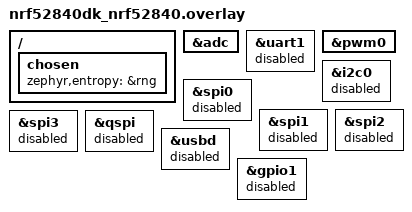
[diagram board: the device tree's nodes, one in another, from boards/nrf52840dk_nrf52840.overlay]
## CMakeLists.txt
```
#
# Copyright (c) 2020 Nordic Semiconductor ASA
#
# SPDX-License-Identifier: LicenseRef-Nordic-5-Clause
#
cmake_minimum_required(VERSION 3.20.0)

list(APPEND BOARD_ROOT ${CMAKE_CURRENT_SOURCE_DIR})

list(INSERT OVERLAY_CONFIG 0 ../common/overlay-ot-defaults.conf)

find_package(Zephyr REQUIRED HINTS $ENV{ZEPHYR_BASE})

project(openthread_coap_client)

# NORDIC SDK APP START
target_sources(app PRIVATE src/coap_client.c
			   src/coap_client_utils.c)

target_include_directories(app PUBLIC ../coap_server/interface)
# NORDIC SDK APP END

# target_sources_ifdef(CONFIG_BT_NUS app PRIVATE src/ble_utils.c)

zephyr_include_directories(include)
add_subdirectory(drivers)
```

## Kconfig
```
#
# Copyright (c) 2020 Nordic Semiconductor ASA
#
# SPDX-License-Identifier: LicenseRef-Nordic-5-Clause
#

menu "Zephyr Kernel"
source "Kconfig.zephyr"
endmenu

rsource "drivers/Kconfig"

module = COAP_CLIENT
module-str = CoAP client
source "${ZEPHYR_BASE}/subsys/logging/Kconfig.template.log_config"

module = COAP_CLIENT_UTILS
module-str = CoAP client utilities
source "${ZEPHYR_BASE}/subsys/logging/Kconfig.template.log_config"
```

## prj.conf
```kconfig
#
# Copyright (c) 2020 Nordic Semiconductor
#
# SPDX-License-Identifier: LicenseRef-Nordic-5-Clause
#


# nRF board library
CONFIG_DK_LIBRARY=y

# Enable CoAP utils and CoAP protocol
CONFIG_COAP_UTILS=y

# Configure sample logging setting
CONFIG_COAP_CLIENT_LOG_LEVEL_DBG=y
CONFIG_COAP_CLIENT_UTILS_LOG_LEVEL_DBG=y
CONFIG_COAP_UTILS_LOG_LEVEL_DBG=y

# Network shell
CONFIG_SHELL=y
CONFIG_OPENTHREAD_SHELL=y
CONFIG_SHELL_ARGC_MAX=26
CONFIG_SHELL_CMD_BUFF_SIZE=416

# Network sockets
CONFIG_NET_SOCKETS=y
CONFIG_NET_SOCKETS_POSIX_NAMES=y
CONFIG_NET_SOCKETS_POLL_MAX=4

# Same network Master Key for client and server
CONFIG_OPENTHREAD_NETWORKKEY="00:11:22:33:44:55:66:77:88:99:aa:bb:cc:dd:ee:ff"

CONFIG_ADC=y
CONFIG_BATTERY=y
```

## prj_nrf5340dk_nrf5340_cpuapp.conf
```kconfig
#
# Copyright (c) 2020 Nordic Semiconductor
#
# SPDX-License-Identifier: LicenseRef-Nordic-5-Clause
#

# nRF board library
CONFIG_DK_LIBRARY=y

# Enable CoAP utils and CoAP protocol
CONFIG_COAP_UTILS=y

# Configure sample logging setting
CONFIG_COAP_CLIENT_LOG_LEVEL_DBG=y
CONFIG_COAP_CLIENT_UTILS_LOG_LEVEL_DBG=y
CONFIG_COAP_UTILS_LOG_LEVEL_DBG=y

# Network shell
CONFIG_NET_SHELL=y
CONFIG_SHELL_ARGC_MAX=26
CONFIG_SHELL_CMD_BUFF_SIZE=416

# Network sockets
CONFIG_NET_SOCKETS=y
CONFIG_NET_SOCKETS_POSIX_NAMES=y
CONFIG_NET_SOCKETS_POLL_MAX=4

# Same network Master Key for client and server
CONFIG_OPENTHREAD_NETWORKKEY="00:11:22:33:44:55:66:77:88:99:aa:bb:cc:dd:ee:ff"

# Default PRNG entropy for nRF53 Series devices is CSPRNG CC312
# which for that purpose is too slow yet
# Use Xoroshiro128+ as PRNG
CONFIG_XOROSHIRO_RANDOM_GENERATOR=y


CONFIG_ADC=y
CONFIG_BATTERY=y
```

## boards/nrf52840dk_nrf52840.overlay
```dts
/* Copyright (c) 2020 Nordic Semiconductor ASA
 *
 * SPDX-License-Identifier: LicenseRef-Nordic-5-Clause
 */

/ {
	/*
	* In some default configurations within the nRF Connect SDK,
	* e.g. on nRF52840, the chosen zephyr,entropy node is &cryptocell.
	* This devicetree overlay ensures that default is overridden wherever it
	* is set, as this application uses the RNG node for entropy exclusively.
	*/
	chosen {
		zephyr,entropy = &rng;
	};
};
&adc {
	status = "okay";
};
&uart1 {
	status = "disabled";
};
&pwm0 {
	status = "okay";
};
&i2c0 {
	status = "disabled";
};
&spi0 {
	status = "disabled";
};
&spi1 {
	status = "disabled";
};
&spi2 {
	status = "disabled";
};
&spi3 {
	status = "disabled";
};
&qspi {
	status = "disabled";
};
&usbd {
	status = "disabled";
};
&gpio1 {
	status = "disabled";
};
```

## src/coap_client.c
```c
/*
 * Copyright (c) 2020 Nordic Semiconductor ASA
 *
 * SPDX-License-Identifier: LicenseRef-Nordic-5-Clause
 */

#include <zephyr.h>
#include <dk_buttons_and_leds.h>
#include <logging/log.h>
#include <ram_pwrdn.h>
#include <device.h>

#include "coap_client_utils.h"

#include <battery.h>

#ifdef CONFIG_BOOTLOADER_MCUBOOT
#include <dfu/mcuboot.h>
#endif

LOG_MODULE_REGISTER(coap_client, CONFIG_COAP_CLIENT_LOG_LEVEL);

#define CONSOLE_LABEL DT_LABEL(DT_CHOSEN(zephyr_console))

#define OT_CONNECTION_LED DK_LED1
#define BLE_CONNECTION_LED DK_LED2
#define MTD_SED_LED DK_LED3

static void on_ot_connect(struct k_work *item)
{
	ARG_UNUSED(item);

	dk_set_led_on(OT_CONNECTION_LED);
}

static void on_ot_disconnect(struct k_work *item)
{
	ARG_UNUSED(item);

	dk_set_led_off(OT_CONNECTION_LED);
}

static void on_mtd_mode_toggle(uint32_t med)
{
#if IS_ENABLED(CONFIG_PM_DEVICE)
	const struct device *cons = device_get_binding(CONSOLE_LABEL);

	if (med) {
		pm_device_state_set(cons, PM_DEVICE_STATE_ACTIVE);
	} else {
		pm_device_state_set(cons, PM_DEVICE_STATE_OFF);
	}
#endif
	dk_set_led(MTD_SED_LED, med);
}

static void on_button_changed(uint32_t button_state, uint32_t has_changed)
{
	uint32_t buttons = button_state & has_changed;

	if (buttons & DK_BTN1_MSK) {
		coap_client_toggle_one_light();
	}

	if (buttons & DK_BTN2_MSK) {
		coap_client_toggle_mesh_lights();
	}

	if (buttons & DK_BTN3_MSK) {
		coap_client_toggle_minimal_sleepy_end_device();
	}

	if (buttons & DK_BTN4_MSK) {
		coap_client_send_provisioning_request();
	}
}

void main(void)
{
	int ret;

	LOG_INF("Start CoAP-client sample");

	if (IS_ENABLED(CONFIG_RAM_POWER_DOWN_LIBRARY)) {
		power_down_unused_ram();
	}

	ret = dk_buttons_init(on_button_changed);
	if (ret) {
		LOG_ERR("Cannot init buttons (error: %d)", ret);
		return;
	}

	ret = dk_leds_init();
	if (ret) {
		LOG_ERR("Cannot init leds, (error: %d)", ret);
		return;
	}

	battery_init();

	coap_client_utils_init(on_ot_connect, on_ot_disconnect,
			       on_mtd_mode_toggle);
}
```

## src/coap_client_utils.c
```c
/*
 * Copyright (c) 2020 Nordic Semiconductor ASA
 *
 * SPDX-License-Identifier: LicenseRef-Nordic-5-Clause
 */

#include <zephyr.h>
#include <coap_server_client_interface.h>
#include <net/coap_utils.h>
#include <logging/log.h>
#include <net/openthread.h>
#include <net/socket.h>
#include <openthread/thread.h>

#include "coap_client_utils.h"

LOG_MODULE_REGISTER(coap_client_utils, CONFIG_COAP_CLIENT_UTILS_LOG_LEVEL);

#define RESPONSE_POLL_PERIOD 100

static uint32_t poll_period;

static bool is_connected;

static struct k_work unicast_light_work;
static struct k_work multicast_light_work;
static struct k_work toggle_MTD_SED_work;
static struct k_work provisioning_work;
static struct k_work on_connect_work;
static struct k_work on_disconnect_work;

mtd_mode_toggle_cb_t on_mtd_mode_toggle;

static struct k_work timer_send_work;
static struct k_timer my_timer;

/* Options supported by the server */
static const char *const light_option[] = {LIGHT_URI_PATH, NULL};
static const char *const provisioning_option[] = {PROVISIONING_URI_PATH,
												  NULL};

/* Thread multicast mesh local address */
static struct sockaddr_in6 multicast_local_addr = {
	.sin6_family = AF_INET6,
	.sin6_port = htons(COAP_PORT),
	.sin6_addr.s6_addr = {0xff, 0x03, 0x00, 0x00, 0x00, 0x00, 0x00, 0x00,
						  0x00, 0x00, 0x00, 0x00, 0x00, 0x00, 0x00, 0x01},
	.sin6_scope_id = 0U};

/* Variable for storing server address acquiring in provisioning handshake */
static char unique_local_addr_str[INET6_ADDRSTRLEN];
static struct sockaddr_in6 unique_local_addr = {
	.sin6_family = AF_INET6,
	.sin6_port = htons(COAP_PORT),
	.sin6_addr.s6_addr = {
		0,
	},
	.sin6_scope_id = 0U};

static void my_timer_send_work_handler(struct k_work *item)
{

		battery_start();

		LOG_INF("Power: %d mV", battery_get_mv());
}

static void my_timer_handler(struct k_timer *dummy)
{
	k_work_submit(&timer_send_work);
}

static bool is_mtd_in_med_mode(otInstance *instance)
{
	return otThreadGetLinkMode(instance).mRxOnWhenIdle;
}

static void poll_period_response_set(void)
{
	otError error;

	otInstance *instance = openthread_get_default_instance();

	if (is_mtd_in_med_mode(instance))
	{
		return;
	}

	if (!poll_period)
	{
		poll_period = otLinkGetPollPeriod(instance);

		error = otLinkSetPollPeriod(instance, RESPONSE_POLL_PERIOD);
		__ASSERT(error == OT_ERROR_NONE, "Failed to set pool period");

		LOG_INF("Poll Period: %dms set", RESPONSE_POLL_PERIOD);
	}
}

static void poll_period_restore(void)
{
	otError error;
	otInstance *instance = openthread_get_default_instance();

	if (is_mtd_in_med_mode(instance))
	{
		return;
	}

	if (poll_period)
	{
		error = otLinkSetPollPeriod(instance, poll_period);
		__ASSERT_NO_MSG(error == OT_ERROR_NONE);

		LOG_INF("Poll Period: %dms restored", poll_period);
		poll_period = 0;
	}
}

static int on_provisioning_reply(const struct coap_packet *response,
								 struct coap_reply *reply,
								 const struct sockaddr *from)
{
	int ret = 0;
	const uint8_t *payload;
	uint16_t payload_size = 0u;

	ARG_UNUSED(reply);
	ARG_UNUSED(from);

	payload = coap_packet_get_payload(response, &payload_size);

	if (payload == NULL ||
		payload_size != sizeof(unique_local_addr.sin6_addr))
	{
		LOG_ERR("Received data is invalid");
		ret = -EINVAL;
		goto exit;
	}

	memcpy(&unique_local_addr.sin6_addr, payload, payload_size);

	if (!inet_ntop(AF_INET6, payload, unique_local_addr_str,
				   INET6_ADDRSTRLEN))
	{
		LOG_ERR("Received data is not IPv6 address: %d", errno);
		ret = -errno;
		goto exit;
	}

	LOG_INF("Received peer address: %s", log_strdup(unique_local_addr_str));

exit:
	if (IS_ENABLED(CONFIG_OPENTHREAD_MTD_SED))
	{
		poll_period_restore();
	}

	return ret;
}

static void toggle_one_light(struct k_work *item)
{
	uint8_t payload = (uint8_t)THREAD_COAP_UTILS_LIGHT_CMD_TOGGLE;

	ARG_UNUSED(item);

	if (unique_local_addr.sin6_addr.s6_addr16[0] == 0)
	{
		LOG_WRN("Peer address not set. Activate 'provisioning' option "
				"on the server side");
		return;
	}

	LOG_INF("Send 'light' request to: %s",
			log_strdup(unique_local_addr_str));
	coap_send_request(COAP_METHOD_PUT,
					  (const struct sockaddr *)&unique_local_addr,
					  light_option, &payload, sizeof(payload), NULL);
}

static void toggle_mesh_lights(struct k_work *item)
{
	static uint8_t command = (uint8_t)THREAD_COAP_UTILS_LIGHT_CMD_OFF;

	ARG_UNUSED(item);

	command = ((command == THREAD_COAP_UTILS_LIGHT_CMD_OFF) ? THREAD_COAP_UTILS_LIGHT_CMD_ON : THREAD_COAP_UTILS_LIGHT_CMD_OFF);

	LOG_INF("Send multicast mesh 'light' request");
	coap_send_request(COAP_METHOD_PUT,
					  (const struct sockaddr *)&multicast_local_addr,
					  light_option, &command, sizeof(command), NULL);
}

static void send_provisioning_request(struct k_work *item)
{
	ARG_UNUSED(item);

	if (IS_ENABLED(CONFIG_OPENTHREAD_MTD_SED))
	{
		/* decrease the polling period for higher responsiveness */
		poll_period_response_set();
	}

	LOG_INF("Send 'provisioning' request");
	coap_send_request(COAP_METHOD_GET,
					  (const struct sockaddr *)&multicast_local_addr,
					  provisioning_option, NULL, 0u, on_provisioning_reply);
}

static void toggle_minimal_sleepy_end_device(struct k_work *item)
{
	otError error;
	otLinkModeConfig mode;
	struct openthread_context *context = openthread_get_default_context();

	__ASSERT_NO_MSG(context != NULL);

	openthread_api_mutex_lock(context);
	mode = otThreadGetLinkMode(context->instance);
	mode.mRxOnWhenIdle = !mode.mRxOnWhenIdle;
	error = otThreadSetLinkMode(context->instance, mode);
	openthread_api_mutex_unlock(context);

	if (error != OT_ERROR_NONE)
	{
		LOG_ERR("Failed to set MLE link mode configuration");
	}
	else
	{
		on_mtd_mode_toggle(mode.mRxOnWhenIdle);
	}
}

static void update_device_state(void)
{
	struct otInstance *instance = openthread_get_default_instance();
	otLinkModeConfig mode = otThreadGetLinkMode(instance);
	on_mtd_mode_toggle(mode.mRxOnWhenIdle);
}

static void on_thread_state_changed(uint32_t flags, void *context)
{
	struct openthread_context *ot_context = context;

	if (flags & OT_CHANGED_THREAD_ROLE)
	{
		switch (otThreadGetDeviceRole(ot_context->instance))
		{
		case OT_DEVICE_ROLE_CHILD:
		case OT_DEVICE_ROLE_ROUTER:
		case OT_DEVICE_ROLE_LEADER:
			k_work_submit(&on_connect_work);
			is_connected = true;
			break;

		case OT_DEVICE_ROLE_DISABLED:
		case OT_DEVICE_ROLE_DETACHED:
		default:
			k_work_submit(&on_disconnect_work);
			is_connected = false;
			break;
		}
	}
}

static void submit_work_if_connected(struct k_work *work)
{
	if (is_connected)
	{
		k_work_submit(work);
	}
	else
	{
		LOG_INF("Connection is broken");
	}
}

void coap_client_utils_init(ot_connection_cb_t on_connect,
							ot_disconnection_cb_t on_disconnect,
							mtd_mode_toggle_cb_t on_toggle)
{
	on_mtd_mode_toggle = on_toggle;

	coap_init(AF_INET6, NULL);

	k_work_init(&on_connect_work, on_connect);
	k_work_init(&on_disconnect_work, on_disconnect);
	k_work_init(&unicast_light_work, toggle_one_light);
	k_work_init(&multicast_light_work, toggle_mesh_lights);
	k_work_init(&provisioning_work, send_provisioning_request);

	k_work_init(&timer_send_work, my_timer_send_work_handler); 
	k_timer_init(&my_timer, my_timer_handler, NULL); 


	openthread_set_state_changed_cb(on_thread_state_changed);
	openthread_start(openthread_get_default_context());

	k_timer_start(&my_timer, K_SECONDS(5), K_SECONDS(10)); 

	if (IS_ENABLED(CONFIG_OPENTHREAD_MTD_SED))
	{
		k_work_init(&toggle_MTD_SED_work,
					toggle_minimal_sleepy_end_device);
		update_device_state();
	}
}

void coap_client_toggle_one_light(void)
{
	submit_work_if_connected(&unicast_light_work);
}

void coap_client_toggle_mesh_lights(void)
{
	submit_work_if_connected(&multicast_light_work);
}

void coap_client_send_provisioning_request(void)
{
	submit_work_if_connected(&provisioning_work);
}

void coap_client_toggle_minimal_sleepy_end_device(void)
{
	if (IS_ENABLED(CONFIG_OPENTHREAD_MTD_SED))
	{
		k_work_submit(&toggle_MTD_SED_work);
	}
}
```
